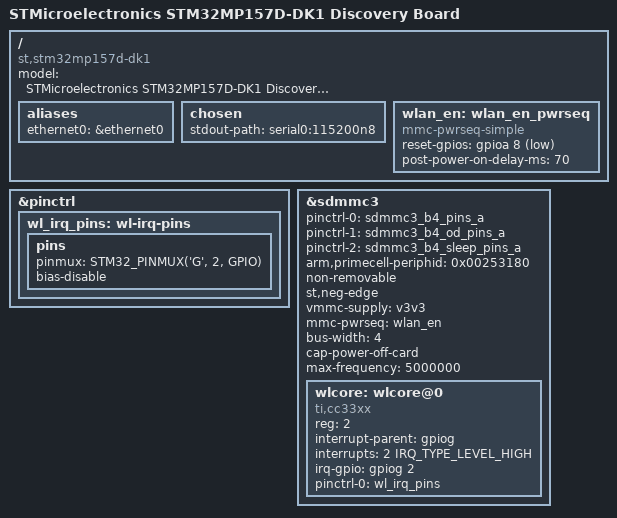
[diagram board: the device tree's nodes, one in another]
// SPDX-License-Identifier: (GPL-2.0-or-later OR BSD-3-Clause)
/*
 * Copyright (C) STMicroelectronics 2022 - All Rights Reserved
 * Author: Alexandre Torgue <alexandre.torgue@foss.st.com> for STMicroelectronics.
 */

/dts-v1/;

#include "stm32mp157.dtsi"
#include "stm32mp15xd.dtsi"
#include "stm32mp15-pinctrl.dtsi"
#include "stm32mp15xxac-pinctrl.dtsi"
#include "stm32mp15xx-dkx.dtsi"
#include "stm32mp157a-dk1-scmi.dtsi"

/ {
	model = "STMicroelectronics STM32MP157D-DK1 Discovery Board";
	compatible = "st,stm32mp157d-dk1", "st,stm32mp157";

	aliases {
		ethernet0 = &ethernet0;
	};

	chosen {
		stdout-path = "serial0:115200n8";
	};

/*
	wlan_en: fixedregulator@10 {
		compatible = "regulator-fixed";
		regulator-name = "wlan-en-regulator";

		gpio = <&gpioa 8 GPIO_ACTIVE_HIGH>;
		regulator-min-microvolt = <1800000>;
		regulator-max-microvolt = <1800000>;
		startup-delay-us = <70000>;
		enable-active-high;
	};
*/

	wlan_en: wlan_en_pwrseq {
		compatible = "mmc-pwrseq-simple";
		reset-gpios = <&gpioa 8 GPIO_ACTIVE_LOW>;
		post-power-on-delay-ms = <70>;
	};
};

&pinctrl {
	wl_irq_pins: wl-irq-pins {
		pins {
			pinmux = <STM32_PINMUX('G', 2, GPIO)>;
			bias-disable;
		};
	};
};

&sdmmc3 {
	pinctrl-names = "default", "opendrain", "sleep";
	pinctrl-0 = <&sdmmc3_b4_pins_a>;
	pinctrl-1 = <&sdmmc3_b4_od_pins_a>;
	pinctrl-2 = <&sdmmc3_b4_sleep_pins_a>;
	status = "okay";

	// ST's suggestion
	// no-sd;
	// no-mmc;

	// THIS WORKS WITH 1BIT BUS WIDTH
	arm,primecell-periphid = <0x00253180>;
	non-removable;
	st,neg-edge;
	vmmc-supply = <&v3v3>;
	mmc-pwrseq = <&wlan_en>;
	bus-width = <4>;
	#address-cells = <1>;
	#size-cells = <0>;
	cap-power-off-card;
	max-frequency = <5000000>;

	wlcore: wlcore@0 {
		compatible = "ti,cc33xx";
		reg = <2>;
		interrupt-parent = <&gpiog>;
		interrupts = <2 IRQ_TYPE_LEVEL_HIGH>;
		irq-gpio = <&gpiog 2 GPIO_ACTIVE_HIGH>;
		pinctrl-names = "default";
		pinctrl-0 = <&wl_irq_pins>;
	};
};
